# cyw20829 register map
Vendor: Infineon Technologies; Series: CYW20829; File version: 1.0
CPU: CM33 r0p1, little endian, MPU, no FPU, VTOR, 3 interrupt priority bits
Registers are 32-bit, read-write, reset 0x0 unless marked. A register's access mark holds for its fields unless they carry their own. Offsets are from the block's base; [hi:lo] are bit positions; lines under a group give offsets from that group; {n}, {i} and the like mark numbered series.

## PERI — Peripheral interconnect
Base 0x40000000
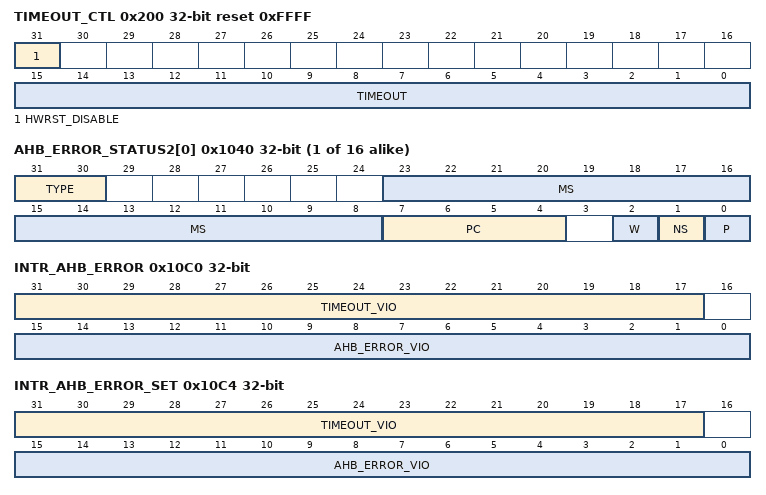
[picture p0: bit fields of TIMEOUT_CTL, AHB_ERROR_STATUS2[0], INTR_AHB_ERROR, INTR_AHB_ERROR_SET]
0x200 TIMEOUT_CTL reset 0xFFFF — Timeout control
  [31] HWRST_DISABLE — This field provides control for HW to reset the slave that is causing the timeout to occur. 1 - no HW reset during timeout. 0 - HW resets the corresponding slave during timeout. This ensures the AHB bus not to be hung after a timeout has occurred. HW asserts the reset only when INTR_AHB_ERROR.TIMEOUT_VIO[i]=1. SW needs to clear the INTR_AHB_ERROR.TIMEOUT_VIO[i]=0 before re-initialize the corresponding slave. ('i' -represents the peripheral group number) Note, SW needs to take care of the implication when clearing this bit when a HW reset has occurred as clearing this bit will cause HW reset de-assert. Note that peripheral group-0 slaves are excluded from timeout (Refer Timeout section in mxsperi.1 BROS for more details).
  [15:0] TIMEOUT — This field specifies a number of peripheral group root undivided (clk_group_root[i]) clock cycles. If an AHB-Lite bus transfer takes more than the specified number of cycles (timeout detection), the bus transfer is terminated with an AHB5 bus error and a timeout status is set. '0x0000'-'0xfffe': Number of peripheral group clock cycles. '0xffff': This value is the default/reset value and specifies that no timeout detection is performed: a bus transfer will never be terminated, and a interrupt will never be generated. Note that TIMEOUT_CTL.TIMEOUT[15:0] in clk_pclk0_root (clk_hf0) is used directly in peripheral group clock domain clk_group_root[i], even if clk_group_root[i] is async to clk_pclk0_root. This is on the assumption that this register is programmed once by SW, remain constant. Following SW programming restrictions apply to TIMEOUT_CTL.TIMEOUT[15:0]. SW should make sure that no other AHB transactions are initiated through PERI before programming this register. SW should make sure that write to TIMEOUT_CTL.TIMEOUT[15:0] is completed by doing a readback. Note that peripheral group-0 slaves are excluded from timeout (Refer Timeout section in mxsperi.1 BROS for more details).
{0x1000+4i} AHB_ERROR_STATUS1[{i}] (i=0..15) ro reset not defined
  [31:0] ADDR — This field indicates the AHB transaction address[31:0] that the AHB error response is detected. This field is valid when INTR_AHB_ERROR.AHB_ERROR_VIO[i] is set for respective peripheral group (i-represent group number). Note that quantity of this register is '16', each register is dedicated to peripheral group-i starting from group-0;
{0x1040+4i} AHB_ERROR_STATUS2[{i}] (i=0..15) ro reset not defined
  [31:30] TYPE, [23:8] MS, [7:4] PC, [2] W, [1] NS, [0] P
{0x1080+4i} AHB_ERROR_STATUS3[{i}] (i=0..15) ro reset not defined
  [4:0] SLAVE_NO — Indicate slave number in respective peripheral group for which Timeout is detected. This field is valid when INTR_AHB_ERROR.TIMEOUT[i] is set for respective peripheral group (i-represents peripheral group). Note that quantity of this register is '16', each register is dedicated to peripheral group-i starting from group-1;
0x10C0 INTR_AHB_ERROR — Interrupt AHB error
  [31:17] TIMEOUT_VIO — HW sets respective bit in this field to '1', when AHB timeout is detected on respective peripheral group. This is 15-bit interrupt register field. Bit-17 indicates AHB timeout is detected in peripheral group-1, Bit-18 indicates AHB timeout is detected in peripheral group-2, .. Bit-31 indicates AHB timeout is detected in peripheral group-15.
  [15:0] AHB_ERROR_VIO — HW sets respective bit in this field to '1', when AHB error is detected on respective peripheral group. This is 16-bit interrupt register field. Bit-0 indicates AHB error response is detected in peripheral group-0, Bit-1 indicates AHB error response is detected in peripheral group-1, .. Bit-15 indicates AHB error response is detected in peripheral group-15.
0x10C4 INTR_AHB_ERROR_SET — Interrupt AHB error set
  [31:17] TIMEOUT_VIO — Write this field with '1' to set corresponding INTR_AHB_ERROR field (a write of '0' has no effect).
  [15:0] AHB_ERROR_VIO — Write this field with '1' to set corresponding INTR_AHB_ERROR field (a write of '0' has no effect).
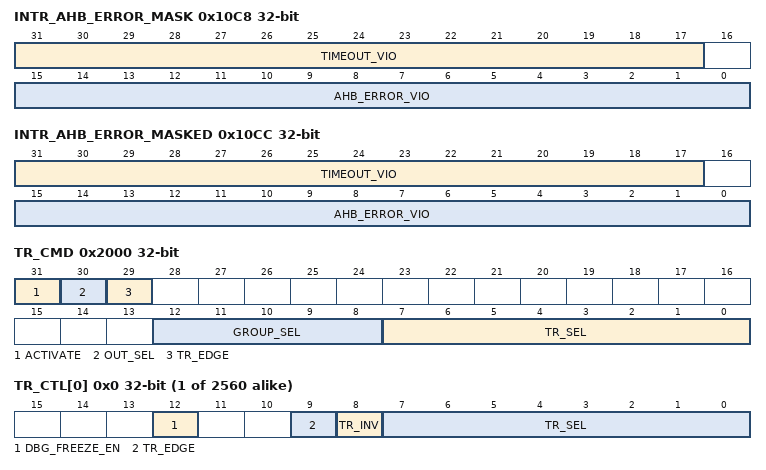
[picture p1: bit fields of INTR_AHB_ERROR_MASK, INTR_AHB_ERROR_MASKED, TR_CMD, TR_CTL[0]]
0x10C8 INTR_AHB_ERROR_MASK — Interrupt AHB error mask
  [31:17] TIMEOUT_VIO — Mask for corresponding field in INTR_AHB_ERROR register.
  [15:0] AHB_ERROR_VIO — Mask for corresponding field in INTR_AHB_ERROR register.
0x10CC INTR_AHB_ERROR_MASKED ro — Interrupt AHB error masked
  [31:17] TIMEOUT_VIO — Logical AND of corresponding INTR_AHB_ERROR and INTR_AHB_ERROR_MASK fields.
  [15:0] AHB_ERROR_VIO — Logical AND of corresponding INTR_AHB_ERROR and INTR_AHB_ERROR_MASK fields.
0x2000 TR_CMD — Trigger command
  [31] ACTIVATE — SW sets this field to '1' to activate (set to '1') a trigger as identified by TR_SEL, TR_EDGE and OUT_SEL. HW sets this field to '0' for edge sensitive triggers AFTER the selected trigger is activated for two clk_peri cycles. Note: when ACTIVATE is '1', SW should not modify the other register fields. SW MUST NOT set ACTIVATE bit to '1' while updating the other register bits simultaneously. At first the SW MUST update the other register bits as needed, and then set ACTIVATE to '1' with a new register write.
  [30] OUT_SEL — Specifies whether trigger activation is for a specific input or output trigger of the trigger multiplexer. Activation of a specific input trigger, will result in activation of all output triggers that have the specific input trigger selected through their TR_OUT_CTL.TR_SEL field. Activation of a specific output trigger, will result in activation of the specified TR_SEL output trigger only. '0': TR_SEL selection and trigger activation is for an input trigger to the trigger multiplexer. '1': TR_SEL selection and trigger activation is for an output trigger from the trigger multiplexer. Note: this field is not used for trigger 1-to-1 groups.
  [29] TR_EDGE — Specifies if the activated trigger is treated as a level sensitive or edge sensitive trigger. '0': level sensitive. The trigger reflects TR_CMD.ACTIVATE. '1': edge sensitive trigger. The trigger is activated for two clk_peri cycles.
  [12:8] GROUP_SEL — Specifies the trigger group: '0'-'15': trigger multiplexer groups. '16'-'31': trigger 1-to-1 groups.
  [7:0] TR_SEL — Specifies the activated trigger when ACTIVATE is '1'. If the specified trigger is not present, the trigger activation has no effect.
0x2004 INFRA_CLK_FORCE — Infrastructure clock force enable
  [0] ENABLED — Infrastructure clock force enable. 0: Disabled 1: Enabled
{0x4000+0x40*i} GR[{i}] (i=0..3) group — Peripheral group structure
  0x00 CLOCK_CTL — Clock control
    [15:8] INT8_DIV — Specifies a group clock divider (from the peripheral clock 'clk_peri' to the group clock 'clk_group[1/2/3/4/5/...15]'). Integer division by (1+INT8_DIV). Allows for integer divisions in the range [1, 256]. Note that this field is retained. However, the counter that is used to implement the division is not and will be initialized by HW to '0' when transitioning from DeepSleep to Active power mode.
  0x10 SL_CTL — Slave control
    [31:0] ENABLED — Slave Enable. Each bit indicates whether the respective slave is enabled. If the slave is disabled, its clock is gated off (constant '0'). Note: For peripheral group 0 slave 0,1, and 2 (the peripheral interconnect MMIO registers), this field is a constant '1' (SW: R): the slave can NOT be disabled. The peripheral IP that drives the Q-Channel back to Clock Controllers need to ensure that it has clock (usually driven by Clk_hf1~N that is only available after CPU configures their roots in the SRSS) to provide back the Q-Channel handshake, if not the deadlock situation will procure. To avoid deadlock mentioned above, all IPs in all groups other than group-0 are disabled (SL_CTL.ENABLED is set to '0') by default after POR (cold boot) (i.e. PERI HW hardcodes local parameter SL_CTL_DEFAULT to 32'hFFFFFFFF for group-0 and to 32'h00000000 for other groups (group-1 to group-15)). Once CPU is up and running & Clk_hf1~N configured, CPU can enable them. The SL_CTL.ENABLED are retained during DEEPSLEEP to avoid enabling configuration after wakeup.
  0x14 SL_CTL2 — Slave control2
    [31:0] RST — Slave reset. Each bit indicates whether the respective slave is enabled. If the slave is under reset, its clock is gated off (constant '0') and its resets are activated. Note: For peripheral group 0 slave 0,1, and 2 (the peripheral interconnect MMIO registers), this field is a constant '0' (SW: R): the slave can NOT be in reset.
  0x18 SL_CTL3 ro — Slave control3
    [31:0] SS_POWERSTATE — Slave status to represent subsystem (SS) IP current power status. Each bit represents the respective IP power state (Note that separate mxsperi peripheral group should be defined for type4 peripheral, should not be mixed with type1/2/3 and same peripheral group can have multiple type4 peripherals) 0 - indiacates IP is in OFF state. 1 - indicates IP is in ON state. This register exists only for peripheral group with type4 peripherals (has its own PPU, P/Q-Channel consolidation and clock gating). This is readonly register connecting to PERI input signal coming from the respective SS IP. Since this register is passthorugh of status signal from peripheral the default value defined is w.r.t. respective IP reset.
  0x20 SL_WOUND — Slave wounding
    [31:0] DISABLED — Slave disabled. Each bit indicates whether the respective slave is disabled. Setting this bit to 1 has the same effect as setting SL_CTL.ENABLED_0 to 0. However, once set to 1, this bit cannot be changed back to 0 anymore. Note: For peripheral group 0 slave 0,1, and 2 (the peripheral interconnect MMIO registers), this field is a constant '0' (SW: R): the slave can NOT be disabled.
{0x8000+0x400*i} TR_GR[{i}] (i=0..9) group — Trigger group
  {0x0+4j} TR_CTL[{j}] (j=0..255) — Trigger control register
    [12] DBG_FREEZE_EN — Specifies if the output trigger is blocked in debug mode. When set high tr_dbg_freeze will block the output trigger generation.
    [9] TR_EDGE — Specifies if the (inverted) output trigger is treated as a level sensitive or edge sensitive trigger. '0': level sensitive. '1': edge sensitive trigger. The (inverted) output trigger duration needs to be at least 2 cycles on the consumer clock. the(inverted) output trigger is synchronized to the consumer clock and a two cycle pulse is generated on the consumer clock.
    [8] TR_INV — Specifies if the output trigger is inverted.
    [7:0] TR_SEL — Specifies input trigger. This field is typically set during the setup of a chip use case scenario. Changing this field while activated triggers are present on the input triggers may result in unpredictable behavior. Note that input trigger 0 (default value) is typically connected to a constant signal level of '0', and as a result will not cause HW activation of the output trigger.
{0xC000+0x400*i} TR_1TO1_GR[{i}] (i=0..4) group — Trigger 1-to-1 group
  {0x0+4j} TR_CTL[{j}] (j=0..255) — Trigger control register
    [12] DBG_FREEZE_EN — Specifies if the output trigger is blocked in debug mode. When set high tr_dbg_freeze will block the output trigger generation.
    [9] TR_EDGE — Specifies if the (inverted) output trigger is treated as a level sensitive or edge sensitive trigger. '0': level sensitive. '1': edge sensitive trigger. The (inverted) output trigger duration needs to be at least 2 cycles on the consumer clock. the(inverted) output trigger is synchronized to the consumer clock and a two cycle pulse is generated on the consumer clock.
    [8] TR_INV — Specifies if the output trigger is inverted.
    [0] TR_SEL — Specifies input trigger: '0'': constant signal level '0'. '1': input trigger.

## Notices in the file
(c) (2016-2026), Infineon Technologies AG
or an affiliate of Infineon Technologies AG.
SPDX-License-Identifier: Apache-2.0
Licensed under the Apache License, Version 2.0 (the "License");
you may not use this file except in compliance with the License.
You may obtain a copy of the License at
http://www.apache.org/licenses/LICENSE-2.0
Unless required by applicable law or agreed to in writing, software
distributed under the License is distributed on an "AS IS" BASIS,
WITHOUT WARRANTIES OR CONDITIONS OF ANY KIND, either express or implied.
See the License for the specific language governing permissions and
limitations under the License.
